AUTOSAR XML (schema 4-3-0)
package /STLASWCs
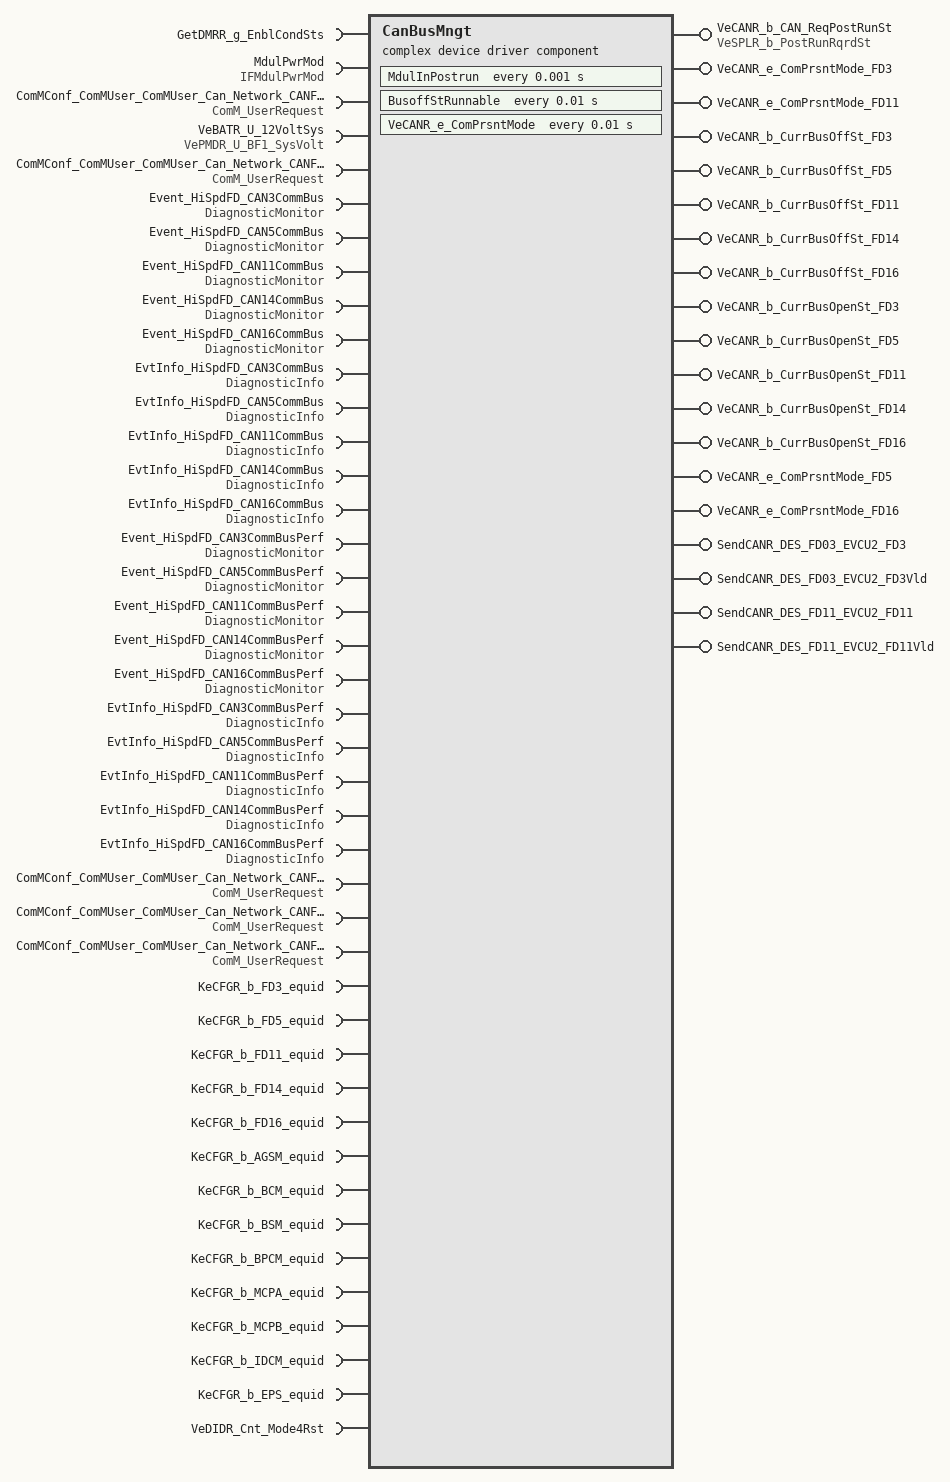
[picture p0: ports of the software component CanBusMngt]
  complex device driver sw component type CanBusMngt  # CAN Bus Management - implements the CAN Power Down functionality, CAN Bus off and other interfaces (such as Wakeup) required to the ComM service component to manage CAN
    provide port VeCANR_b_CAN_ReqPostRunSt: nonqueued-sender-com-spec{data-element=VeSPLR_b_PostRunRqrdSt, init-value=0}, provided-interface=VeSPLR_b_PostRunRqrdSt
    provide port VeCANR_e_ComPrsntMode_FD3: nonqueued-sender-com-spec{data-element=VeCANR_e_ComPrsntMode_FD3, init-value=Value:0}, provided-interface=VeCANR_e_ComPrsntMode_FD3
    5 x require port:
      GetDMRR_g_EnblCondSts: client-com-spec=GetDMRR_g_EnblCondSts, required-interface=GetDMRR_g_EnblCondSts
      MdulPwrMod: mode-switch-receiver-com-spec=AppMode_MDGP_ESH_Mode, required-interface=IFMdulPwrMod
      ComMConf_ComMUser_ComMUser_Can_Network_CANFD_3_Channel: client-com-spec=GetCurrentComMode, required-interface=ComM_UserRequest
      VeBATR_U_12VoltSys: required-interface=VePMDR_U_BF1_SysVolt
      ComMConf_ComMUser_ComMUser_Can_Network_CANFD_5_Channel: client-com-spec=GetCurrentComMode, required-interface=ComM_UserRequest
    provide port VeCANR_e_ComPrsntMode_FD11: nonqueued-sender-com-spec{data-element=VeCANR_e_ComPrsntMode_FD11, init-value=Value:0}, provided-interface=VeCANR_e_ComPrsntMode_FD11
    28 x require port:
      Event_HiSpdFD_CAN3CommBus: client-com-spec=SetEventStatus, required-interface=DiagnosticMonitor
      Event_HiSpdFD_CAN5CommBus: client-com-spec=SetEventStatus, required-interface=DiagnosticMonitor
      Event_HiSpdFD_CAN11CommBus: client-com-spec=SetEventStatus, required-interface=DiagnosticMonitor
      Event_HiSpdFD_CAN14CommBus: client-com-spec=SetEventStatus, required-interface=DiagnosticMonitor
      Event_HiSpdFD_CAN16CommBus: client-com-spec=SetEventStatus, required-interface=DiagnosticMonitor
      EvtInfo_HiSpdFD_CAN3CommBus: client-com-spec=GetEventStatus, required-interface=DiagnosticInfo
      EvtInfo_HiSpdFD_CAN5CommBus: client-com-spec=GetEventStatus, required-interface=DiagnosticInfo
      EvtInfo_HiSpdFD_CAN11CommBus: client-com-spec=GetEventStatus, required-interface=DiagnosticInfo
      EvtInfo_HiSpdFD_CAN14CommBus: client-com-spec=GetEventStatus, required-interface=DiagnosticInfo
      EvtInfo_HiSpdFD_CAN16CommBus: client-com-spec=GetEventStatus, required-interface=DiagnosticInfo
      Event_HiSpdFD_CAN3CommBusPerf: client-com-spec=SetEventStatus, required-interface=DiagnosticMonitor
      Event_HiSpdFD_CAN5CommBusPerf: client-com-spec=SetEventStatus, required-interface=DiagnosticMonitor
      Event_HiSpdFD_CAN11CommBusPerf: client-com-spec=SetEventStatus, required-interface=DiagnosticMonitor
      Event_HiSpdFD_CAN14CommBusPerf: client-com-spec=SetEventStatus, required-interface=DiagnosticMonitor
      Event_HiSpdFD_CAN16CommBusPerf: client-com-spec=SetEventStatus, required-interface=DiagnosticMonitor
      EvtInfo_HiSpdFD_CAN3CommBusPerf: client-com-spec=GetEventStatus, required-interface=DiagnosticInfo
      EvtInfo_HiSpdFD_CAN5CommBusPerf: client-com-spec=GetEventStatus, required-interface=DiagnosticInfo
      EvtInfo_HiSpdFD_CAN11CommBusPerf: client-com-spec=GetEventStatus, required-interface=DiagnosticInfo
      EvtInfo_HiSpdFD_CAN14CommBusPerf: client-com-spec=GetEventStatus, required-interface=DiagnosticInfo
      EvtInfo_HiSpdFD_CAN16CommBusPerf: client-com-spec=GetEventStatus, required-interface=DiagnosticInfo
      ComMConf_ComMUser_ComMUser_Can_Network_CANFD_11_Channel: client-com-spec=GetCurrentComMode, required-interface=ComM_UserRequest
      ComMConf_ComMUser_ComMUser_Can_Network_CANFD_16_Channel: client-com-spec=GetCurrentComMode, required-interface=ComM_UserRequest
      ComMConf_ComMUser_ComMUser_Can_Network_CANFD_14_Channel: client-com-spec=GetCurrentComMode, required-interface=ComM_UserRequest
      KeCFGR_b_FD3_equid: parameter-require-com-spec{init-value=Value:0, parameter=KeCFGR_b_FD3_equid}, required-interface=KeCFGR_b_FD3_equid
      KeCFGR_b_FD5_equid: parameter-require-com-spec{init-value=Value:0, parameter=KeCFGR_b_FD5_equid}, required-interface=KeCFGR_b_FD5_equid
      KeCFGR_b_FD11_equid: parameter-require-com-spec{init-value=Value:0, parameter=KeCFGR_b_FD11_equid}, required-interface=KeCFGR_b_FD11_equid
      KeCFGR_b_FD14_equid: parameter-require-com-spec{init-value=Value:0, parameter=KeCFGR_b_FD14_equid}, required-interface=KeCFGR_b_FD14_equid
      KeCFGR_b_FD16_equid: parameter-require-com-spec{init-value=Value:0, parameter=KeCFGR_b_FD16_equid}, required-interface=KeCFGR_b_FD16_equid
    12 x provide port:
      VeCANR_b_CurrBusOffSt_FD3: nonqueued-sender-com-spec{data-element=VeCANR_b_CurrBusOffSt_FD3, init-value=0}, provided-interface=VeCANR_b_CurrBusOffSt_FD3  # CAN FD3 bus off state
      VeCANR_b_CurrBusOffSt_FD5: nonqueued-sender-com-spec{data-element=VeCANR_b_CurrBusOffSt_FD5, init-value=0}, provided-interface=VeCANR_b_CurrBusOffSt_FD5  # CAN FD5 bus off state
      VeCANR_b_CurrBusOffSt_FD11: nonqueued-sender-com-spec{data-element=VeCANR_b_CurrBusOffSt_FD11, init-value=0}, provided-interface=VeCANR_b_CurrBusOffSt_FD11  # CAN FD11 bus off state
      VeCANR_b_CurrBusOffSt_FD14: nonqueued-sender-com-spec{data-element=VeCANR_b_CurrBusOffSt_FD14, init-value=0}, provided-interface=VeCANR_b_CurrBusOffSt_FD14  # CAN FD14 bus off state
      VeCANR_b_CurrBusOffSt_FD16: nonqueued-sender-com-spec{data-element=VeCANR_b_CurrBusOffSt_FD16, init-value=0}, provided-interface=VeCANR_b_CurrBusOffSt_FD16  # CAN FD16 bus off state
      VeCANR_b_CurrBusOpenSt_FD3: nonqueued-sender-com-spec{data-element=VeCANR_b_CurrBusOpenSt_FD3, init-value=0}, provided-interface=VeCANR_b_CurrBusOpenSt_FD3  # CAN FD3 bus open state
      VeCANR_b_CurrBusOpenSt_FD5: nonqueued-sender-com-spec{data-element=VeCANR_b_CurrBusOpenSt_FD5, init-value=0}, provided-interface=VeCANR_b_CurrBusOpenSt_FD5  # CAN FD5 bus open state
      VeCANR_b_CurrBusOpenSt_FD11: nonqueued-sender-com-spec{data-element=VeCANR_b_CurrBusOpenSt_FD11, init-value=0}, provided-interface=VeCANR_b_CurrBusOpenSt_FD11  # CAN FD11 bus open state
      VeCANR_b_CurrBusOpenSt_FD14: nonqueued-sender-com-spec{data-element=VeCANR_b_CurrBusOpenSt_FD14, init-value=0}, provided-interface=VeCANR_b_CurrBusOpenSt_FD14  # CAN FD14 bus open state
      VeCANR_b_CurrBusOpenSt_FD16: nonqueued-sender-com-spec{data-element=VeCANR_b_CurrBusOpenSt_FD16, init-value=0}, provided-interface=VeCANR_b_CurrBusOpenSt_FD16  # CAN FD16 bus open state
      VeCANR_e_ComPrsntMode_FD5: nonqueued-sender-com-spec{data-element=VeCANR_e_ComPrsntMode_FD5, init-value=Value:0}, provided-interface=VeCANR_e_ComPrsntMode_FD5
      VeCANR_e_ComPrsntMode_FD16: nonqueued-sender-com-spec{data-element=VeCANR_e_ComPrsntMode_FD16, init-value=Value:0}, provided-interface=VeCANR_e_ComPrsntMode_FD16
    8 x require port:
      KeCFGR_b_AGSM_equid: parameter-require-com-spec{init-value=Value:0, parameter=KeCFGR_b_AGSM_equid}, required-interface=KeCFGR_b_AGSM_equid
      KeCFGR_b_BCM_equid: parameter-require-com-spec{init-value=Value:0, parameter=KeCFGR_b_BCM_equid}, required-interface=KeCFGR_b_BCM_equid
      KeCFGR_b_BSM_equid: parameter-require-com-spec{init-value=Value:0, parameter=KeCFGR_b_BSM_equid}, required-interface=KeCFGR_b_BSM_equid
      KeCFGR_b_BPCM_equid: parameter-require-com-spec{init-value=Value:0, parameter=KeCFGR_b_BPCM_equid}, required-interface=KeCFGR_b_BPCM_equid
      KeCFGR_b_MCPA_equid: parameter-require-com-spec{init-value=Value:0, parameter=KeCFGR_b_MCPA_equid}, required-interface=KeCFGR_b_MCPA_equid
      KeCFGR_b_MCPB_equid: parameter-require-com-spec{init-value=Value:0, parameter=KeCFGR_b_MCPB_equid}, required-interface=KeCFGR_b_MCPB_equid
      KeCFGR_b_IDCM_equid: parameter-require-com-spec{init-value=Value:0, parameter=KeCFGR_b_IDCM_equid}, required-interface=KeCFGR_b_IDCM_equid
      KeCFGR_b_EPS_equid: parameter-require-com-spec{init-value=Value:0, parameter=KeCFGR_b_EPS_equid}, required-interface=KeCFGR_b_EPS_equid
    4 x provide port:
      SendCANR_DES_FD03_EVCU2_FD3: nonqueued-sender-com-spec{data-element=SendCANR_DES_FD03_EVCU2_FD3, init-value=0}, provided-interface=SendCANR_DES_FD03_EVCU2_FD3
      SendCANR_DES_FD03_EVCU2_FD3Vld: nonqueued-sender-com-spec{data-element=SendCANR_DES_FD03_EVCU2_FD3Vld, init-value=1}, provided-interface=SendCANR_DES_FD03_EVCU2_FD3Vld
      SendCANR_DES_FD11_EVCU2_FD11: nonqueued-sender-com-spec{data-element=SendCANR_DES_FD11_EVCU2_FD11, init-value=0}, provided-interface=SendCANR_DES_FD11_EVCU2_FD11
      SendCANR_DES_FD11_EVCU2_FD11Vld: nonqueued-sender-com-spec{data-element=SendCANR_DES_FD11_EVCU2_FD11Vld, init-value=1}, provided-interface=SendCANR_DES_FD11_EVCU2_FD11Vld
    require port VeDIDR_Cnt_Mode4Rst: nonqueued-receiver-com-spec{data-element=VeDIDR_Cnt_Mode4Rst, init-value=Value:0}, required-interface=VeDIDR_Cnt_Mode4Rst
    behavior IBCanBusMngt: data-type-mapping=[BswMMappingSet, DTS_DcmDiagnosticSessionControl, DTS_DcmEcuReset, DTS_DcmControlDTCSetting, DTS_DcmCommunicationControl_Can_Network_CANFD_3, ADTtoIDTMapping, ADTtoIDTMapping], handle-termination-and-restart=NO-SUPPORT
      init event IninEve: start-on-event=IninRunnable  # CAN Bus Management SWC initialization runnable
      timing event FastTEA1: start-on-event=MdulInPostrun, period=0.001  # Cyclic event activated when module is in POST RUN mode
        disabled-mode:
          MdulPwrMod.AppMode_MDGP_ESH_Mode.RUN
          MdulPwrMod.AppMode_MDGP_ESH_Mode.STARTUP
          MdulPwrMod.AppMode_MDGP_ESH_Mode.SHUTDOWN
          MdulPwrMod.AppMode_MDGP_ESH_Mode.WAKEUP
      timing event MedTEA1: start-on-event=BusoffStRunnable, period=0.01
        disabled-mode:
          MdulPwrMod.AppMode_MDGP_ESH_Mode.STARTUP
          MdulPwrMod.AppMode_MDGP_ESH_Mode.SHUTDOWN
          MdulPwrMod.AppMode_MDGP_ESH_Mode.WAKEUP
      timing event MedTEAComPrsntMod: start-on-event=VeCANR_e_ComPrsntMode, period=0.01  # Timing runnable triggered every 10ms
      explicit-inter-runnable-variables:
        13 x data, all with init-value=Value:0:
          VeCAND_Cnt_PrevMode4RstBusMngt: type=uint8  # Static variable to hold previous value of VeDIDR_Cnt_Mode4Rst
          VeCANR_Cnt_BascCAN_OvrrnCntr: type=uint16  # This IRV holds the basic CAN overrun counters.
          VeCANR_Cnt_FullCAN_OvrrnCntr: type=uint16  # This IRV holds the full CAN overrun counter.
          VeCANR_e_ComPrsntModeFD3: type=ComM_ModeType  # IRV provides the Present Communication mode of Channel FD3
          VeCANR_e_PostRunSt: type=uint16  # POST RUN state machine state variable
          VeCANR_t_BattVoltVldTmr: type=uint16  # Battery voltage valid timer
          VeCANR_t_CAN_PwrDwnDlyTmrForRPM: type=uint16  # Power down timer for delay after RPM reaches zero
          VeCANR_t_CAN_PwrDwnFnlDlyTmr: type=uint16  # Final power down delay timer
          VeCANR_t_U0001_1SecTmr: type=uint16  # Bus off mode 1 sec timer
          VeCANR_t_U0001_NormCom1SecTmr: type=uint16  # Normal communication mode 1 second timer
          VeCANR_U_BattVolt: type=float32  # Buss off diagnostic battery voltage
          VeCANR_t_U0074_NormCom1SecTmr: type=uint16  # Normal communication mode 1 second timer
          VeCANR_e_ComPrsntModeFD11: type=ComM_ModeType  # IRV provides the Present Communication mode of Channel FD11
      4 x runnable:
        BusoffStRunnable: symbol=CanBusMngt_BusoffStRunnable
          data-read-access:
            access DRA_VeDIDR_Cnt_Mode4Rst_VeDIDR_Cnt_Mode4Rst: accessed-variable=VeDIDR_Cnt_Mode4Rst.VeDIDR_Cnt_Mode4Rst
          data-send-points:
            16 x access:
              DSP_SendCANR_DES_FD03_EVCU2_FD3_SendCANR_DES_FD03_EVCU2_FD3: accessed-variable=SendCANR_DES_FD03_EVCU2_FD3.SendCANR_DES_FD03_EVCU2_FD3
              DSP_SendCANR_DES_FD03_EVCU2_FD3Vld_SendCANR_DES_FD03_EVCU2_FD3Vld: accessed-variable=SendCANR_DES_FD03_EVCU2_FD3Vld.SendCANR_DES_FD03_EVCU2_FD3Vld
              DSP_SendCANR_DES_FD11_EVCU2_FD11_SendCANR_DES_FD11_EVCU2_FD11: accessed-variable=SendCANR_DES_FD11_EVCU2_FD11.SendCANR_DES_FD11_EVCU2_FD11
              DSP_SendCANR_DES_FD11_EVCU2_FD11Vld_SendCANR_DES_FD11_EVCU2_FD11Vld: accessed-variable=SendCANR_DES_FD11_EVCU2_FD11Vld.SendCANR_DES_FD11_EVCU2_FD11Vld
              DSP_VeCANR_b_CurrBusOffSt_FD11_VeCANR_b_CurrBusOffSt_FD11: accessed-variable=VeCANR_b_CurrBusOffSt_FD11.VeCANR_b_CurrBusOffSt_FD11
              DSP_VeCANR_b_CurrBusOffSt_FD14_VeCANR_b_CurrBusOffSt_FD14: accessed-variable=VeCANR_b_CurrBusOffSt_FD14.VeCANR_b_CurrBusOffSt_FD14
              DSP_VeCANR_b_CurrBusOffSt_FD16_VeCANR_b_CurrBusOffSt_FD16: accessed-variable=VeCANR_b_CurrBusOffSt_FD16.VeCANR_b_CurrBusOffSt_FD16
              DSP_VeCANR_b_CurrBusOffSt_FD3_VeCANR_b_CurrBusOffSt_FD3: accessed-variable=VeCANR_b_CurrBusOffSt_FD3.VeCANR_b_CurrBusOffSt_FD3
              DSP_VeCANR_b_CurrBusOffSt_FD5_VeCANR_b_CurrBusOffSt_FD5: accessed-variable=VeCANR_b_CurrBusOffSt_FD5.VeCANR_b_CurrBusOffSt_FD5
              DSP_VeCANR_b_CurrBusOpenSt_FD11_VeCANR_b_CurrBusOpenSt_FD11: accessed-variable=VeCANR_b_CurrBusOpenSt_FD11.VeCANR_b_CurrBusOpenSt_FD11
              DSP_VeCANR_b_CurrBusOpenSt_FD14_VeCANR_b_CurrBusOpenSt_FD14: accessed-variable=VeCANR_b_CurrBusOpenSt_FD14.VeCANR_b_CurrBusOpenSt_FD14
              DSP_VeCANR_b_CurrBusOpenSt_FD16_VeCANR_b_CurrBusOpenSt_FD16: accessed-variable=VeCANR_b_CurrBusOpenSt_FD16.VeCANR_b_CurrBusOpenSt_FD16
              DSP_VeCANR_b_CurrBusOpenSt_FD3_VeCANR_b_CurrBusOpenSt_FD3: accessed-variable=VeCANR_b_CurrBusOpenSt_FD3.VeCANR_b_CurrBusOpenSt_FD3
              DSP_VeCANR_b_CurrBusOpenSt_FD5_VeCANR_b_CurrBusOpenSt_FD5: accessed-variable=VeCANR_b_CurrBusOpenSt_FD5.VeCANR_b_CurrBusOpenSt_FD5
              DSP_VeCANR_e_ComPrsntMode_FD11_VeCANR_e_ComPrsntMode_FD11: accessed-variable=VeCANR_e_ComPrsntMode_FD11.VeCANR_e_ComPrsntMode_FD11
              DSP_VeCANR_e_ComPrsntMode_FD3_VeCANR_e_ComPrsntMode_FD3: accessed-variable=VeCANR_e_ComPrsntMode_FD3.VeCANR_e_ComPrsntMode_FD3
          41 x parameter access:
            SCPVA_KeCAND_b_U1056_FltEnbl: accessed-parameter=KeCAND_b_U1056_FltEnbl
            SCPVA_KeCAND_g_U1056_GlbEnblMask: accessed-parameter=KeCAND_g_U1056_GlbEnblMask
            SCPVA_KeCANR_t_BusOffBattVoltVldTi: accessed-parameter=KeCANR_t_BusOffBattVoltVldTi
            SCPVA_KeCANR_t_BusOffDiagFltDematureTi: accessed-parameter=KeCANR_t_BusOffDiagFltDematureTi
            SCPVA_KeCANR_t_BusOffDiagFltMatureTi: accessed-parameter=KeCANR_t_BusOffDiagFltMatureTi
            SCPVA_KeCANR_U_BusOffDiagBattVoltMax: accessed-parameter=KeCANR_U_BusOffDiagBattVoltMax
            SCPVA_KeCANR_U_BusOffDiagBattVoltMin: accessed-parameter=KeCANR_U_BusOffDiagBattVoltMin
            SCPVA_KeCAND_g_BusOpenMsgEnblMaskFD11: accessed-parameter=KeCAND_g_BusOpenMsgEnblMaskFD11
            SCPVA_KeCAND_g_BusOpenMsgEnblMaskFD14: accessed-parameter=KeCAND_g_BusOpenMsgEnblMaskFD14
            SCPVA_KeCAND_g_BusOpenMsgEnblMaskFD16: accessed-parameter=KeCAND_g_BusOpenMsgEnblMaskFD16
            SCPVA_KeCAND_g_BusOpenMsgEnblMaskFD3: accessed-parameter=KeCAND_g_BusOpenMsgEnblMaskFD3
            SCPVA_KeCAND_g_BusOpenMsgEnblMaskFD5: accessed-parameter=KeCAND_g_BusOpenMsgEnblMaskFD5
            CPA_KeCFGR_b_AGSM_equid_KeCFGR_b_AGSM_equid: accessed-parameter=KeCFGR_b_AGSM_equid.KeCFGR_b_AGSM_equid
            CPA_KeCFGR_b_BCM_equid_KeCFGR_b_BCM_equid: accessed-parameter=KeCFGR_b_BCM_equid.KeCFGR_b_BCM_equid
            CPA_KeCFGR_b_BPCM_equid_KeCFGR_b_BPCM_equid: accessed-parameter=KeCFGR_b_BPCM_equid.KeCFGR_b_BPCM_equid
            CPA_KeCFGR_b_BSM_equid_KeCFGR_b_BSM_equid: accessed-parameter=KeCFGR_b_BSM_equid.KeCFGR_b_BSM_equid
            CPA_KeCFGR_b_EPS_equid_KeCFGR_b_EPS_equid: accessed-parameter=KeCFGR_b_EPS_equid.KeCFGR_b_EPS_equid
            CPA_KeCFGR_b_FD11_equid_KeCFGR_b_FD11_equid: accessed-parameter=KeCFGR_b_FD11_equid.KeCFGR_b_FD11_equid
            CPA_KeCFGR_b_FD14_equid_KeCFGR_b_FD14_equid: accessed-parameter=KeCFGR_b_FD14_equid.KeCFGR_b_FD14_equid
            CPA_KeCFGR_b_FD16_equid_KeCFGR_b_FD16_equid: accessed-parameter=KeCFGR_b_FD16_equid.KeCFGR_b_FD16_equid
            CPA_KeCFGR_b_FD3_equid_KeCFGR_b_FD3_equid: accessed-parameter=KeCFGR_b_FD3_equid.KeCFGR_b_FD3_equid
            CPA_KeCFGR_b_FD5_equid_KeCFGR_b_FD5_equid: accessed-parameter=KeCFGR_b_FD5_equid.KeCFGR_b_FD5_equid
            CPA_KeCFGR_b_IDCM_equid_KeCFGR_b_IDCM_equid: accessed-parameter=KeCFGR_b_IDCM_equid.KeCFGR_b_IDCM_equid
            CPA_KeCFGR_b_MCPA_equid_KeCFGR_b_MCPA_equid: accessed-parameter=KeCFGR_b_MCPA_equid.KeCFGR_b_MCPA_equid
            CPA_KeCFGR_b_MCPB_equid_KeCFGR_b_MCPB_equid: accessed-parameter=KeCFGR_b_MCPB_equid.KeCFGR_b_MCPB_equid
            SCPVA_KeCAND_b_U106B_FltEnbl: accessed-parameter=KeCAND_b_U106B_FltEnbl
            SCPVA_KeCAND_b_U106F_FltEnbl: accessed-parameter=KeCAND_b_U106F_FltEnbl
            SCPVA_KeCAND_b_U1075_FltEnbl: accessed-parameter=KeCAND_b_U1075_FltEnbl
            SCPVA_KeCAND_b_U1079_FltEnbl: accessed-parameter=KeCAND_b_U1079_FltEnbl
            SCPVA_KeCAND_g_U1057_GlbEnblMask: accessed-parameter=KeCAND_g_U1057_GlbEnblMask
            SCPVA_KeCAND_g_U106B_GlbEnblMask: accessed-parameter=KeCAND_g_U106B_GlbEnblMask
            SCPVA_KeCAND_g_U106C_GlbEnblMask: accessed-parameter=KeCAND_g_U106C_GlbEnblMask
            SCPVA_KeCAND_g_U106F_GlbEnblMask: accessed-parameter=KeCAND_g_U106F_GlbEnblMask
            SCPVA_KeCAND_g_U1070_GlbEnblMask: accessed-parameter=KeCAND_g_U1070_GlbEnblMask
            SCPVA_KeCAND_g_U1075_GlbEnblMask: accessed-parameter=KeCAND_g_U1075_GlbEnblMask
            SCPVA_KeCAND_g_U1076_GlbEnblMask: accessed-parameter=KeCAND_g_U1076_GlbEnblMask
            SCPVA_KeCAND_g_U1079_GlbEnblMask: accessed-parameter=KeCAND_g_U1079_GlbEnblMask
            SCPVA_KeCAND_g_U107A_GlbEnblMask: accessed-parameter=KeCAND_g_U107A_GlbEnblMask
            SCPVA_KeCAND_b_U1057_FltEnbl: accessed-parameter=KeCAND_b_U1057_FltEnbl
            SCPVA_KeCAND_b_U106C_FltEnbl: accessed-parameter=KeCAND_b_U106C_FltEnbl
            SCPVA_KeCAND_b_U1070_FltEnbl: accessed-parameter=KeCAND_b_U1070_FltEnbl
          read-local-variables:
            5 x access:
              IRVRA_VeCANR_t_BattVoltVldTmr: accessed-variable=VeCANR_t_BattVoltVldTmr
              IRVRA_VeCANR_U_BattVolt: accessed-variable=VeCANR_U_BattVolt
              IRVRA_VeCAND_Cnt_PrevMode4RstBusMngt: accessed-variable=VeCAND_Cnt_PrevMode4RstBusMngt
              IRVRA_VeCANR_e_ComPrsntModeFD11: accessed-variable=VeCANR_e_ComPrsntModeFD11
              IRVRA_VeCANR_e_ComPrsntModeFD3: accessed-variable=VeCANR_e_ComPrsntModeFD3
          26 x sync call, all with timeout=0.0:
            SSCP_ComMConf_ComMUser_ComMUser_Can_Network_CANFD_3_Channel_GetCurrentComMode: operation=ComMConf_ComMUser_ComMUser_Can_Network_CANFD_3_Channel.GetCurrentComMode
            SSCP_ComMConf_ComMUser_ComMUser_Can_Network_CANFD_5_Channel_GetCurrentComMode: operation=ComMConf_ComMUser_ComMUser_Can_Network_CANFD_5_Channel.GetCurrentComMode
            SSCP_ComMConf_ComMUser_ComMUser_Can_Network_CANFD_11_Channel_GetCurrentComMode: operation=ComMConf_ComMUser_ComMUser_Can_Network_CANFD_11_Channel.GetCurrentComMode
            SSCP_ComMConf_ComMUser_ComMUser_Can_Network_CANFD_14_Channel_GetCurrentComMode: operation=ComMConf_ComMUser_ComMUser_Can_Network_CANFD_14_Channel.GetCurrentComMode
            SSCP_ComMConf_ComMUser_ComMUser_Can_Network_CANFD_16_Channel_GetCurrentComMode: operation=ComMConf_ComMUser_ComMUser_Can_Network_CANFD_16_Channel.GetCurrentComMode
            SSCP_Event_HiSpdFD_CAN11CommBus_SetEventStatus: operation=Event_HiSpdFD_CAN11CommBus.SetEventStatus
            SSCP_Event_HiSpdFD_CAN11CommBusPerf_SetEventStatus: operation=Event_HiSpdFD_CAN11CommBusPerf.SetEventStatus
            SSCP_Event_HiSpdFD_CAN14CommBus_SetEventStatus: operation=Event_HiSpdFD_CAN14CommBus.SetEventStatus
            SSCP_Event_HiSpdFD_CAN14CommBusPerf_SetEventStatus: operation=Event_HiSpdFD_CAN14CommBusPerf.SetEventStatus
            SSCP_Event_HiSpdFD_CAN16CommBus_SetEventStatus: operation=Event_HiSpdFD_CAN16CommBus.SetEventStatus
            SSCP_Event_HiSpdFD_CAN3CommBus_SetEventStatus: operation=Event_HiSpdFD_CAN3CommBus.SetEventStatus
            SSCP_Event_HiSpdFD_CAN3CommBusPerf_SetEventStatus: operation=Event_HiSpdFD_CAN3CommBusPerf.SetEventStatus
            SSCP_Event_HiSpdFD_CAN5CommBus_SetEventStatus: operation=Event_HiSpdFD_CAN5CommBus.SetEventStatus
            SSCP_Event_HiSpdFD_CAN5CommBusPerf_SetEventStatus: operation=Event_HiSpdFD_CAN5CommBusPerf.SetEventStatus
            SSCP_EvtInfo_HiSpdFD_CAN11CommBus_GetEventStatus: operation=EvtInfo_HiSpdFD_CAN11CommBus.GetEventStatus
            SSCP_EvtInfo_HiSpdFD_CAN11CommBusPerf_GetEventStatus: operation=EvtInfo_HiSpdFD_CAN11CommBusPerf.GetEventStatus
            SSCP_EvtInfo_HiSpdFD_CAN14CommBus_GetEventStatus: operation=EvtInfo_HiSpdFD_CAN14CommBus.GetEventStatus
            SSCP_EvtInfo_HiSpdFD_CAN14CommBusPerf_GetEventStatus: operation=EvtInfo_HiSpdFD_CAN14CommBusPerf.GetEventStatus
            SSCP_EvtInfo_HiSpdFD_CAN16CommBus_GetEventStatus: operation=EvtInfo_HiSpdFD_CAN16CommBus.GetEventStatus
            SSCP_EvtInfo_HiSpdFD_CAN16CommBusPerf_GetEventStatus: operation=EvtInfo_HiSpdFD_CAN16CommBusPerf.GetEventStatus
            SSCP_EvtInfo_HiSpdFD_CAN3CommBus_GetEventStatus: operation=EvtInfo_HiSpdFD_CAN3CommBus.GetEventStatus
            SSCP_EvtInfo_HiSpdFD_CAN3CommBusPerf_GetEventStatus: operation=EvtInfo_HiSpdFD_CAN3CommBusPerf.GetEventStatus
            SSCP_EvtInfo_HiSpdFD_CAN5CommBus_GetEventStatus: operation=EvtInfo_HiSpdFD_CAN5CommBus.GetEventStatus
            SSCP_EvtInfo_HiSpdFD_CAN5CommBusPerf_GetEventStatus: operation=EvtInfo_HiSpdFD_CAN5CommBusPerf.GetEventStatus
            SSCP_Event_HiSpdFD_CAN16CommBusPerf_SetEventStatus: operation=Event_HiSpdFD_CAN16CommBusPerf.SetEventStatus
            SSCP_GetDMRR_g_EnblCondSts_GetDMRR_g_EnblCondSts: operation=GetDMRR_g_EnblCondSts.GetDMRR_g_EnblCondSts
          written-local-variables:
            access IRVWA_VeCANR_t_BattVoltVldTmr: accessed-variable=VeCANR_t_BattVoltVldTmr
            access IRVWA_VeCANR_U_BattVolt: accessed-variable=VeCANR_U_BattVolt
        IninRunnable: symbol=CanBusMngt_IninRunnable  # CAN Bus Management SWC initialization runnable
          data-send-points:
            access DSP_VeCANR_b_CAN_ReqPostRunSt_VeSPLR_b_PostRunRqrdSt: accessed-variable=VeCANR_b_CAN_ReqPostRunSt.VeSPLR_b_PostRunRqrdSt
          data-write-access:
            12 x access:
              DWA_VeCANR_b_CurrBusOffSt_FD11_VeCANR_b_CurrBusOffSt_FD11: accessed-variable=VeCANR_b_CurrBusOffSt_FD11.VeCANR_b_CurrBusOffSt_FD11
              DWA_VeCANR_b_CurrBusOffSt_FD14_VeCANR_b_CurrBusOffSt_FD14: accessed-variable=VeCANR_b_CurrBusOffSt_FD14.VeCANR_b_CurrBusOffSt_FD14
              DWA_VeCANR_b_CurrBusOffSt_FD16_VeCANR_b_CurrBusOffSt_FD16: accessed-variable=VeCANR_b_CurrBusOffSt_FD16.VeCANR_b_CurrBusOffSt_FD16
              DWA_VeCANR_b_CurrBusOffSt_FD3_VeCANR_b_CurrBusOffSt_FD3: accessed-variable=VeCANR_b_CurrBusOffSt_FD3.VeCANR_b_CurrBusOffSt_FD3
              DWA_VeCANR_b_CurrBusOffSt_FD5_VeCANR_b_CurrBusOffSt_FD5: accessed-variable=VeCANR_b_CurrBusOffSt_FD5.VeCANR_b_CurrBusOffSt_FD5
              DWA_VeCANR_b_CurrBusOpenSt_FD11_VeCANR_b_CurrBusOpenSt_FD11: accessed-variable=VeCANR_b_CurrBusOpenSt_FD11.VeCANR_b_CurrBusOpenSt_FD11
              DWA_VeCANR_b_CurrBusOpenSt_FD14_VeCANR_b_CurrBusOpenSt_FD14: accessed-variable=VeCANR_b_CurrBusOpenSt_FD14.VeCANR_b_CurrBusOpenSt_FD14
              DWA_VeCANR_b_CurrBusOpenSt_FD16_VeCANR_b_CurrBusOpenSt_FD16: accessed-variable=VeCANR_b_CurrBusOpenSt_FD16.VeCANR_b_CurrBusOpenSt_FD16
              DWA_VeCANR_b_CurrBusOpenSt_FD3_VeCANR_b_CurrBusOpenSt_FD3: accessed-variable=VeCANR_b_CurrBusOpenSt_FD3.VeCANR_b_CurrBusOpenSt_FD3
              DWA_VeCANR_b_CurrBusOpenSt_FD5_VeCANR_b_CurrBusOpenSt_FD5: accessed-variable=VeCANR_b_CurrBusOpenSt_FD5.VeCANR_b_CurrBusOpenSt_FD5
              DWA_VeCANR_e_ComPrsntMode_FD11_VeCANR_e_ComPrsntMode_FD11: accessed-variable=VeCANR_e_ComPrsntMode_FD11.VeCANR_e_ComPrsntMode_FD11
              DWA_VeCANR_e_ComPrsntMode_FD3_VeCANR_e_ComPrsntMode_FD3: accessed-variable=VeCANR_e_ComPrsntMode_FD3.VeCANR_e_ComPrsntMode_FD3
          5 x parameter access:
            CPA_KeCFGR_b_FD11_equid_KeCFGR_b_FD11_equid: accessed-parameter=KeCFGR_b_FD11_equid.KeCFGR_b_FD11_equid
            CPA_KeCFGR_b_FD14_equid_KeCFGR_b_FD14_equid: accessed-parameter=KeCFGR_b_FD14_equid.KeCFGR_b_FD14_equid
            CPA_KeCFGR_b_FD16_equid_KeCFGR_b_FD16_equid: accessed-parameter=KeCFGR_b_FD16_equid.KeCFGR_b_FD16_equid
            CPA_KeCFGR_b_FD3_equid_KeCFGR_b_FD3_equid: accessed-parameter=KeCFGR_b_FD3_equid.KeCFGR_b_FD3_equid
            CPA_KeCFGR_b_FD5_equid_KeCFGR_b_FD5_equid: accessed-parameter=KeCFGR_b_FD5_equid.KeCFGR_b_FD5_equid
          read-local-variables:
            access IRVRA_VeCANR_e_PostRunSt: accessed-variable=VeCANR_e_PostRunSt
            access IRVRA_VeCANR_e_ComPrsntModeFD11: accessed-variable=VeCANR_e_ComPrsntModeFD11
            access IRVRA_VeCANR_e_ComPrsntModeFD3: accessed-variable=VeCANR_e_ComPrsntModeFD3
          written-local-variables:
            access IRVWA_VeCANR_e_PostRunSt: accessed-variable=VeCANR_e_PostRunSt
            access IRVWA_VeCANR_t_BattVoltVldTmr: accessed-variable=VeCANR_t_BattVoltVldTmr
            access IRVWA_VeCANR_U_BattVolt: accessed-variable=VeCANR_U_BattVolt
        MdulInPostrun: symbol=CanBusMngt_MdulInPostrun  # Runnable tied to cyclic event which runs only during POST RUN mode.
          data-send-points:
            access DSP_VeSPLR_b_PostRunRqrdSt_0: accessed-variable=VeCANR_b_CAN_ReqPostRunSt.VeSPLR_b_PostRunRqrdSt
          mode-access-point mode-group=MdulPwrMod.AppMode_MDGP_ESH_Mode:
            ident MAP_MdulPwrMod_AppMode_MDGP_ESH_Mode
          5 x parameter access:
            CPA_KeCFGR_b_FD11_equid_KeCFGR_b_FD11_equid: accessed-parameter=KeCFGR_b_FD11_equid.KeCFGR_b_FD11_equid
            CPA_KeCFGR_b_FD14_equid_KeCFGR_b_FD14_equid: accessed-parameter=KeCFGR_b_FD14_equid.KeCFGR_b_FD14_equid
            CPA_KeCFGR_b_FD16_equid_KeCFGR_b_FD16_equid: accessed-parameter=KeCFGR_b_FD16_equid.KeCFGR_b_FD16_equid
            CPA_KeCFGR_b_FD3_equid_KeCFGR_b_FD3_equid: accessed-parameter=KeCFGR_b_FD3_equid.KeCFGR_b_FD3_equid
            CPA_KeCFGR_b_FD5_equid_KeCFGR_b_FD5_equid: accessed-parameter=KeCFGR_b_FD5_equid.KeCFGR_b_FD5_equid
          read-local-variables:
            access IRVRA_VeCANR_e_PostRunSt: accessed-variable=VeCANR_e_PostRunSt
            access IRVRA_VeCANR_t_CAN_PwrDwnDlyTmrForRPM: accessed-variable=VeCANR_t_CAN_PwrDwnDlyTmrForRPM
            access IRVRA_VeCANR_t_CAN_PwrDwnFnlDlyTmr: accessed-variable=VeCANR_t_CAN_PwrDwnFnlDlyTmr
          4 x sync call, all with timeout=0.0:
            SSCP_UR_ComMUser_CT_Can_Atlantis_High_Channel_CT_Can_Atlantis_High_GetCurrentComMode: operation=ComMConf_ComMUser_ComMUser_Can_Network_CANFD_3_Channel.GetCurrentComMode
            SSCP_UR_ComMUser_CT_Can_Atlantis_High_Channel_CT_Can_Atlantis_High_RequestComMode: operation=ComMConf_ComMUser_ComMUser_Can_Network_CANFD_3_Channel.RequestComMode
            SSCP_UR_ComMUser_CT_Can_Pvt_Channel_CT_Can_Pvt_GetCurrentComMode: operation=ComMConf_ComMUser_ComMUser_Can_Network_CANFD_5_Channel.GetCurrentComMode
            SSCP_UR_ComMUser_CT_Can_Pvt_Channel_CT_Can_Pvt_RequestComMode: operation=ComMConf_ComMUser_ComMUser_Can_Network_CANFD_5_Channel.RequestComMode
          written-local-variables:
            access IRVWA_VeCANR_e_PostRunSt: accessed-variable=VeCANR_e_PostRunSt
            access IRVWA_VeCANR_t_CAN_PwrDwnDlyTmrForRPM: accessed-variable=VeCANR_t_CAN_PwrDwnDlyTmrForRPM
            access IRVWA_VeCANR_t_CAN_PwrDwnFnlDlyTmr: accessed-variable=VeCANR_t_CAN_PwrDwnFnlDlyTmr
        VeCANR_e_ComPrsntMode: symbol=CanBusMngt_VeCANR_e_ComPrsntMode  # This runnable reads the present communication mode from COMM module and provides it to Application through Data element VeCANR_e_ComPrsntMode, also stores communication mode of each FlexCAN channel in respective IRV
          data-send-points:
            access DSP_VeCANR_e_ComPrsntMode_FD11_VeCANR_e_ComPrsntMode_FD11: accessed-variable=VeCANR_e_ComPrsntMode_FD11.VeCANR_e_ComPrsntMode_FD11
            access DSP_VeCANR_e_ComPrsntMode_FD3_VeCANR_e_ComPrsntMode_FD3: accessed-variable=VeCANR_e_ComPrsntMode_FD3.VeCANR_e_ComPrsntMode_FD3
          data-write-access:
            4 x access:
              DWA_SendCANR_DES_FD03_EVCU2_FD3_SendCANR_DES_FD03_EVCU2_FD3: accessed-variable=SendCANR_DES_FD03_EVCU2_FD3.SendCANR_DES_FD03_EVCU2_FD3
              DWA_SendCANR_DES_FD03_EVCU2_FD3Vld_SendCANR_DES_FD03_EVCU2_FD3Vld: accessed-variable=SendCANR_DES_FD03_EVCU2_FD3Vld.SendCANR_DES_FD03_EVCU2_FD3Vld
              DWA_SendCANR_DES_FD11_EVCU2_FD11_SendCANR_DES_FD11_EVCU2_FD11: accessed-variable=SendCANR_DES_FD11_EVCU2_FD11.SendCANR_DES_FD11_EVCU2_FD11
              DWA_SendCANR_DES_FD11_EVCU2_FD11Vld_SendCANR_DES_FD11_EVCU2_FD11Vld: accessed-variable=SendCANR_DES_FD11_EVCU2_FD11Vld.SendCANR_DES_FD11_EVCU2_FD11Vld
          parameter access SCPVA_KeCAND_b_U106B_FltEnbl: accessed-parameter=KeCAND_b_U106B_FltEnbl
          parameter access SCPVA_KeCAND_b_U1056_FltEnbl: accessed-parameter=KeCAND_b_U1056_FltEnbl
          sync call SSCP_UR_ComMUser_CT_Can_Atlantis_High_Channel_CT_Can_Atlantis_High_GetCurrentComMode: operation=ComMConf_ComMUser_ComMUser_Can_Network_CANFD_3_Channel.GetCurrentComMode, timeout=0.0
          sync call SSCP_UR_ComMUser_CT_Can_Pvt_Channel_CT_Can_Pvt_GetCurrentComMode: operation=ComMConf_ComMUser_ComMUser_Can_Network_CANFD_5_Channel.GetCurrentComMode, timeout=0.0
          written-local-variables:
            access IRVWA_VeCANR_e_ComPrsntModeFD11: accessed-variable=VeCANR_e_ComPrsntModeFD11
            access IRVWA_VeCANR_e_ComPrsntModeFD3: accessed-variable=VeCANR_e_ComPrsntModeFD3
      shared-parameters:
        29 x parameter data prototype:
          KeCAND_b_U1056_FltEnbl: type=ADTSBoolean, init-value=1  # This Calibration parameter is used to enable or disable the setting of DTC FD3 CanBusOffFlt
          KeCAND_g_U1056_GlbEnblMask: type=uint32, init-value=Value:0  # FD3 CAN busoff fault enable condition cal
          KeCANR_t_BusOffBattVoltVldTi: type=uint16, init-value=Value:100  # Time that must elapse with battery voltage valid before maturing bus off fault.
          KeCANR_t_BusOffDiagFltDematureTi: type=ADTSMilliSec, init-value=4  # Time that must elapse in normal communication mode before de-maturing bus off fault.
          KeCANR_t_BusOffDiagFltMatureTi: type=ADTSMilliSec, init-value=4  # Time that must elapse in bus off mode before maturing bus off fault.
          KeCANR_U_BusOffDiagBattVoltMax: type=float32, init-value=Value:15.735  # Maximum battery voltage for which bus off diagnostics is enabled.
          KeCANR_U_BusOffDiagBattVoltMin: type=float32, init-value=Value:9.9907  # Minimum battery voltage for which bus off diagnostics is enabled.
          KeCAND_g_BusOpenMsgEnblMaskFD3: type=uint8, init-value=Value:255  # Bitwise data to enable/disable pre-configured messages for monitoring CAN Bus Open
          KeCAND_g_BusOpenMsgEnblMaskFD5: type=uint8, init-value=Value:255  # Bitwise data to enable/disable pre-configured messages for monitoring CAN Bus Open
          KeCAND_g_BusOpenMsgEnblMaskFD11: type=uint8, init-value=Value:255  # Bitwise data to enable/disable pre-configured messages for monitoring CAN Bus Open
          KeCAND_g_BusOpenMsgEnblMaskFD14: type=uint8, init-value=Value:255  # Bitwise data to enable/disable pre-configured messages for monitoring CAN Bus Open
          KeCAND_g_BusOpenMsgEnblMaskFD16: type=uint8, init-value=Value:255  # Bitwise data to enable/disable pre-configured messages for monitoring CAN Bus Open
          KeCAND_b_U1075_FltEnbl: type=ADTSBoolean, init-value=1  # This Calibration parameter is used to enable or disable the setting of DTC FD5 CanBusOffFlt
          KeCAND_b_U106B_FltEnbl: type=ADTSBoolean, init-value=1  # This Calibration parameter is used to enable or disable the setting of DTC FD11 CanBusOffFlt
          KeCAND_b_U106F_FltEnbl: type=ADTSBoolean, init-value=1  # This Calibration parameter is used to enable or disable the setting of DTC FD14 CanBusOffFlt
          KeCAND_b_U1079_FltEnbl: type=ADTSBoolean, init-value=1  # This Calibration parameter is used to enable or disable the setting of DTC FD16 CanBusOffFlt
          KeCAND_g_U106B_GlbEnblMask: type=uint32, init-value=Value:1  # FD11 CAN busoff fault enable condition cal
          KeCAND_g_U106F_GlbEnblMask: type=uint32, init-value=Value:1  # FD14 CAN busoff fault enable condition cal
          KeCAND_g_U1079_GlbEnblMask: type=uint32, init-value=Value:1  # FD16 CAN busoff fault enable condition cal
          KeCAND_g_U1075_GlbEnblMask: type=uint32, init-value=Value:1  # FD5 CAN busoff fault enable condition cal
          KeCAND_g_U1057_GlbEnblMask: type=uint32, init-value=Value:1  # FD3 CAN bus open fault enable condition cal
          KeCAND_g_U1076_GlbEnblMask: type=uint32, init-value=Value:1  # FD5 CAN bus open fault enable condition cal
          KeCAND_g_U106C_GlbEnblMask: type=uint32, init-value=Value:1  # FD11 CAN bus open fault enable condition cal
          KeCAND_g_U1070_GlbEnblMask: type=uint32, init-value=Value:1  # FD14 CAN bus open fault enable condition cal
          KeCAND_g_U107A_GlbEnblMask: type=uint32, init-value=Value:1  # FD16 CAN bus open fault enable condition cal
          KeCAND_b_U1057_FltEnbl: type=ADTSBoolean, init-value=1  # This Calibration parameter is used to enable or disable the setting of DTC FD3 Can Bus Open Flt
          KeCAND_b_U106C_FltEnbl: type=ADTSBoolean, init-value=1  # This Calibration parameter is used to enable or disable the setting of DTC FD11 Can Bus Open Flt
          KeCAND_b_U1070_FltEnbl: type=ADTSBoolean, init-value=1  # This Calibration parameter is used to enable or disable the setting of DTC FD14 Can Bus Open Flt
          KeCAND_b_U107A_FltEnbl: type=ADTSBoolean, init-value=1  # This Calibration parameter is used to enable or disable the setting of DTC FD16 CanBusOpenFlt
